AUTOSAR XML (schema 4-0-3)
package /ComponentTypes
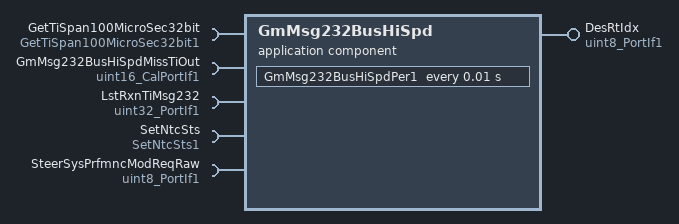
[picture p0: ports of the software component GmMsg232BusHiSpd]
  application sw component type GmMsg232BusHiSpd
    provide port DesRtIdx: nonqueued-sender-com-spec{data-element=Val, init-value=0}, provided-interface=uint8_PortIf1
    5 x require port:
      GetTiSpan100MicroSec32bit: required-interface=GetTiSpan100MicroSec32bit1
      GmMsg232BusHiSpdMissTiOut: parameter-require-com-spec{init-value=500, parameter=Val}, required-interface=uint16_CalPortIf1
      LstRxnTiMsg232: nonqueued-receiver-com-spec{data-element=Val, filter=data-filter-type=ALWAYS, init-value=0}, required-interface=uint32_PortIf1
      SetNtcSts: required-interface=SetNtcSts1
      SteerSysPrfmncModReqRaw: nonqueued-receiver-com-spec{data-element=Val, filter=data-filter-type=ALWAYS, init-value=0}, required-interface=uint8_PortIf1
    behavior GmMsg232BusHiSpd_InternalBehavior: data-type-mapping=Nexteer
      ar-typed-per-instance-memorys:
        data GmMsg232BusHiSpdPrevDesRtIdx: sw-calibration-access=READ-ONLY, type=uint8
      timing event TMT_GM0C9HSPer1: start-on-event=GmMsg232BusHiSpdPer1, period=0.01
      runnable GmMsg232BusHiSpdPer1
        data-receive-point-by-arguments:
          access REC_Msg0C9HSLstRxnTi_Val: accessed-variable=LstRxnTiMsg232.Val
          access REC_SteerSysPrfmncModReqRaw_Val: accessed-variable=SteerSysPrfmncModReqRaw.Val
        data-send-points:
          access SEND_DesRtIdx_Val: accessed-variable=DesRtIdx.Val
        sync call SC_GetTiSpan100MicroSec32bit_Oper: operation=GetTiSpan100MicroSec32bit.Oper, timeout=0
        sync call SC_SetNtcSts_Oper: operation=SetNtcSts.Oper, timeout=0
  swc implementation GmMsg232BusHiSpd_Implementation: behavior=GmMsg232BusHiSpd_InternalBehavior
    code-descriptors:
      code Default: artifact-descriptors=autosar-engineering-object={short-label=Default, category=SWSRC}
